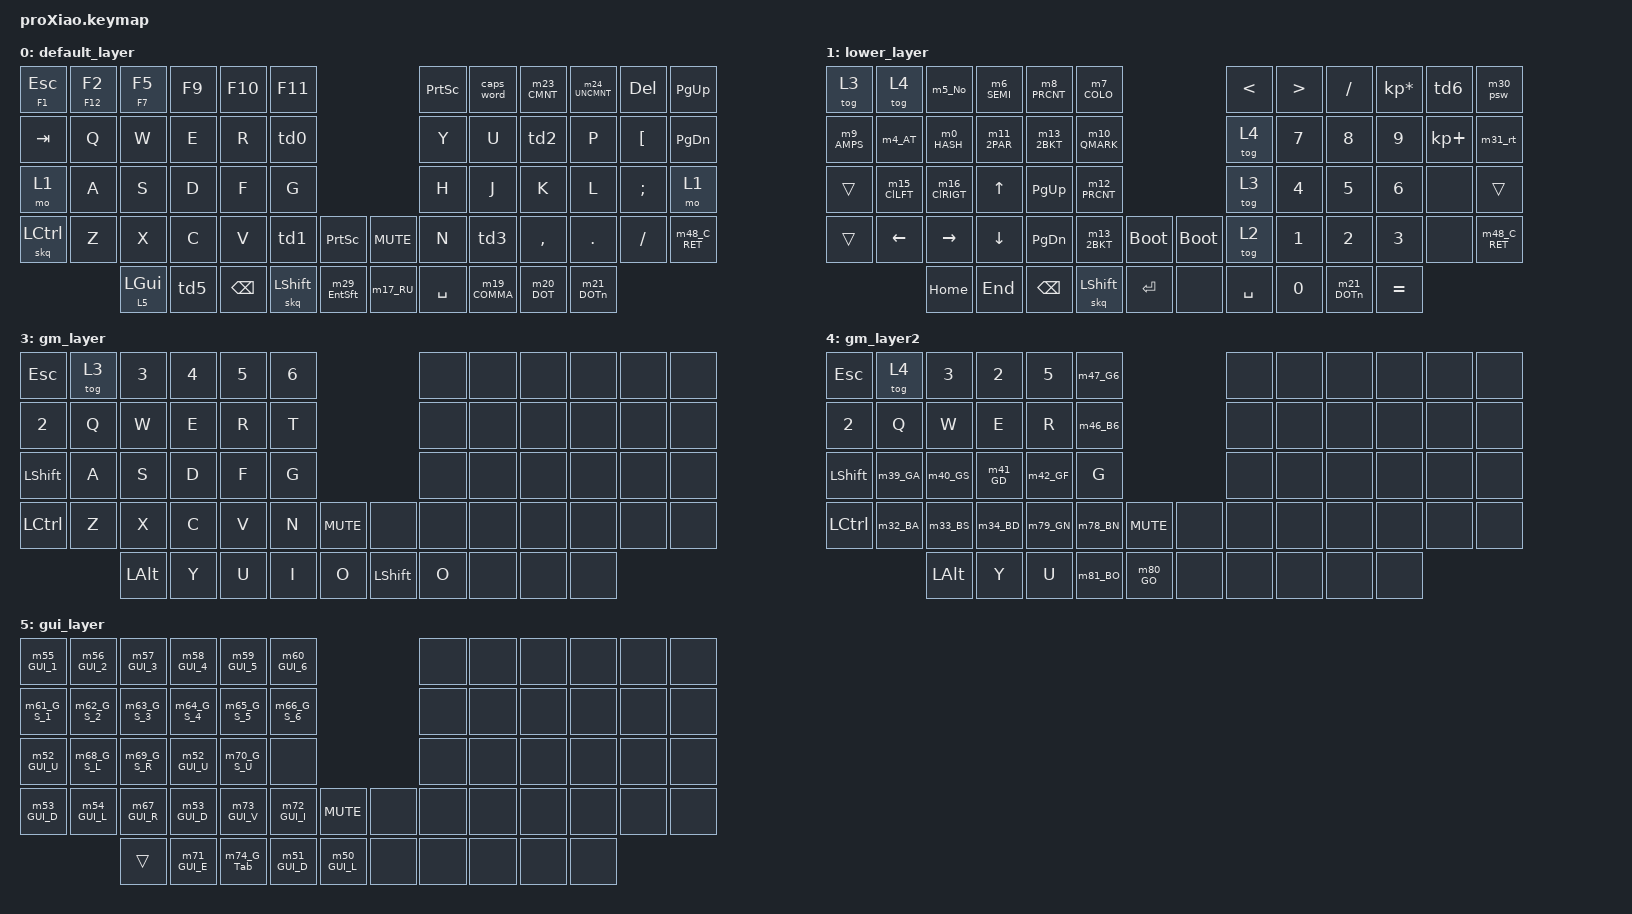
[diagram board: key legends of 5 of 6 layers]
/*
 * Copyright (c) 2020 The ZMK Contributors
 *
 * SPDX-License-Identifier: MIT
 */

#include <behaviors.dtsi>
#include <dt-bindings/zmk/keys.h>
#include <dt-bindings/zmk/bt.h>

&caps_word {
    continue-list = <RBKT>, <GRAVE>, <COMMA>, <DOT>, <FSLH>;
};

/ {
    behaviors {

         td0: tap_dance_0 {
            compatible = "zmk,behavior-tap-dance";
            label = "TAP_DANCE_0";
            #binding-cells = <0>;
            tapping-term-ms = <200>;
            bindings = <&kp T>, <&kp GRAVE>, <&none>;
        };
        td1: tap_dance_1 {
            compatible = "zmk,behavior-tap-dance";
            label = "TAP_DANCE_1";
            #binding-cells = <0>;
            tapping-term-ms = <200>;
            bindings = <&kp B>, <&kp Q>, <&none>;
        };
        td2: tap_dance_2 {
            compatible = "zmk,behavior-tap-dance";
            label = "TAP_DANCE_2";
            #binding-cells = <0>;
            tapping-term-ms = <200>;
            bindings = <&kp I>, <&kp O>, <&none>;
        };
        td3: tap_dance_3 {
            compatible = "zmk,behavior-tap-dance";
            label = "TAP_DANCE_3";
            #binding-cells = <0>;
            tapping-term-ms = <200>;
            bindings = <&kp M>, <&kp RBKT>, <&none>;
        };
        td4: tap_dance_4 {
            compatible = "zmk,behavior-tap-dance";
            label = "TAP_DANCE_4";
            #binding-cells = <0>;
            tapping-term-ms = <200>;
            bindings = <&sk LSHIFT>, <&kp RBKT>, <&none>;
        };
        td5: tap_dance_5 {
            compatible = "zmk,behavior-tap-dance";
            label = "TAP_DANCE_4";
            #binding-cells = <0>;
            tapping-term-ms = <200>;
            bindings = <&kp LALT>, <&m22_AltF4>, <&none>;
        };
        td6: tap_dance_6 {
            compatible = "zmk,behavior-tap-dance";
            label = "TAP_DANCE_6";
            #binding-cells = <0>;
            tapping-term-ms = <200>;
            bindings = <&kp KP_MINUS>, <&kp UNDER>, <&none>;
        };
    };
    macros {
        m0_HASH: m0_HASH {
            label = "m0_HASH";
            compatible = "zmk,behavior-macro";
            #binding-cells = <0>;
            bindings
                = <&macro_press &kp LEFT_ALT>
                , <&macro_tap &kp KP_N3 &kp KP_N5>
                , <&macro_release &kp LEFT_ALT>
                ;
        };
        m1_DQT: m1_DQT {
            label = "m1_DQT";
            compatible = "zmk,behavior-macro";
            #binding-cells = <0>;
            bindings
                = <&macro_press &kp LEFT_ALT>
                , <&macro_tap &kp KP_N3 &kp KP_N4>
                , <&macro_release &kp LEFT_ALT>
                ;
        };
        m2_2DQT: m2_2DQT {
            label = "m2_2DQT";
            compatible = "zmk,behavior-macro";
            #binding-cells = <0>;
            bindings
                = <&macro_press &kp LEFT_ALT>
                , <&macro_tap &kp KP_N3 &kp KP_N4>
                , <&macro_release &kp LEFT_ALT>
                , <&macro_tap &kp LEFT>
                , <&macro_press &kp LEFT_ALT>
                , <&macro_tap &kp KP_N3 &kp KP_N4>
                , <&macro_release &kp LEFT_ALT>
                ;
        };
        m3_EXCL: m3_EXCL {
            label = "m3_EXCL";
            compatible = "zmk,behavior-macro";
            #binding-cells = <0>;
            bindings
                = <&macro_press &kp LEFT_ALT>
                , <&macro_tap &kp KP_N3 &kp KP_N3>
                , <&macro_release &kp LEFT_ALT>
                ;
        };
        m4_AT: m4_AT {
            label = "m4_AT";
            compatible = "zmk,behavior-macro";
            #binding-cells = <0>;
            bindings
                = <&macro_press &kp LEFT_ALT>
                , <&macro_tap &kp KP_N6 &kp KP_N4>
                , <&macro_release &kp LEFT_ALT>
                ;
        };
        m5_No: m5_No {
            label = "m5_No";
            compatible = "zmk,behavior-macro";
            #binding-cells = <0>;
            bindings
                = <&macro_press &kp LEFT_ALT>
                , <&macro_tap &kp KP_N2 &kp KP_N5 &kp KP_N2>
                , <&macro_release &kp LEFT_ALT>
                ;
        };
        m6_SEMI: m6_SEMI {
            label = "m6_SEMI";
            compatible = "zmk,behavior-macro";
            #binding-cells = <0>;
            bindings
                = <&macro_press &kp LEFT_ALT>
                , <&macro_tap &kp KP_N5 &kp KP_N9>
                , <&macro_release &kp LEFT_ALT>
                ;
        };
        m7_COLO: m7_COLO {
            label = "m7_COLO";
            compatible = "zmk,behavior-macro";
            #binding-cells = <0>;
            bindings
                = <&macro_press &kp LEFT_ALT>
                , <&macro_tap &kp KP_N5 &kp KP_N8>
                , <&macro_release &kp LEFT_ALT>
                ;
        };
        m8_PRCNT: m8_PRCNT {
            label = "m8_PRCNT";
            compatible = "zmk,behavior-macro";
            #binding-cells = <0>;
            bindings
                = <&macro_press &kp LEFT_ALT>
                , <&macro_tap &kp KP_N3 &kp KP_N7>
                , <&macro_release &kp LEFT_ALT>
                ;
        };
        m9_AMPS: m9_AMPS {
            label = "m9_AMPS";
            compatible = "zmk,behavior-macro";
            #binding-cells = <0>;
            bindings
                = <&macro_press &kp LEFT_ALT>
                , <&macro_tap &kp KP_N3 &kp KP_N8>
                , <&macro_release &kp LEFT_ALT>
                ;
        };
        m10_QMARK: m10_QMARK {
            label = "m10_QMARK";
            compatible = "zmk,behavior-macro";
            #binding-cells = <0>;
            bindings
                = <&macro_press &kp LEFT_ALT>
                , <&macro_tap &kp KP_N6 &kp KP_N3>
                , <&macro_release &kp LEFT_ALT>
                ;
        };
        m11_2PAR: m11_2PAR {
            label = "m11_2PAR";
            compatible = "zmk,behavior-macro";
            #binding-cells = <0>;
            bindings
                = <&macro_press &kp LEFT_ALT>
                , <&macro_tap &kp KP_N4 &kp KP_N1>
                , <&macro_release &kp LEFT_ALT>
                , <&macro_tap &kp LEFT>
                , <&macro_press &kp LEFT_ALT>
                , <&macro_tap &kp KP_N4 &kp KP_N0>
                , <&macro_release &kp LEFT_ALT>
                ;
        };
        m12_PRCNT: m12_PRCNT {
            label = "m12_PRCNT";
            compatible = "zmk,behavior-macro";
            #binding-cells = <0>;
            bindings
                = <&macro_press &kp LEFT_ALT>
                , <&macro_tap &kp KP_N3 &kp KP_N7>
                , <&macro_release &kp LEFT_ALT>
                ;
        };
        m13_2BKT: m13_2BKT {
            label = "m13_2BKT";
            compatible = "zmk,behavior-macro";
            #binding-cells = <0>;
            bindings
                = <&macro_press &kp LEFT_ALT>
                , <&macro_tap &kp KP_N9 &kp KP_N1>
                , <&macro_release &kp LEFT_ALT>
                , <&macro_tap &kp LEFT>
                , <&macro_press &kp LEFT_ALT>
                , <&macro_tap &kp KP_N9 &kp KP_N3>
                , <&macro_release &kp LEFT_ALT>
                ;
        };
        m14_2BRC: m14_2BRC {
            label = "m14_2BRC";
            compatible = "zmk,behavior-macro";
            #binding-cells = <0>;
            bindings
                = <&macro_press &kp LEFT_ALT>
                , <&macro_tap &kp KP_N1 &kp KP_N2 &kp KP_N3>
                , <&macro_release &kp LEFT_ALT>
                , <&macro_tap &kp LEFT>
                , <&macro_press &kp LEFT_ALT>
                , <&macro_tap &kp KP_N4 &kp KP_N1 &kp KP_N5>
                , <&macro_release &kp LEFT_ALT>
                ;
        };
         m15_ClLFT: m15_ClLFT {
            label = "m15_ClLFT";
            compatible = "zmk,behavior-macro";
            #binding-cells = <0>;
            bindings
                = <&macro_press &kp LCTRL>
                , <&macro_tap &kp LEFT>
                , <&macro_release &kp LCTRL>
                ;
        };
         m16_ClRIGT: m16_ClRIGT {
            label = "m16_ClRIGT";
            compatible = "zmk,behavior-macro";
            #binding-cells = <0>;
            bindings
                = <&macro_press &kp LCTRL>
                , <&macro_tap &kp RIGHT>
                , <&macro_release &kp LCTRL>
                ;
        };
         m17_RU: m17_RU {
            label = "m17_RU";
            compatible = "zmk,behavior-macro";
            #binding-cells = <0>;
            bindings
                = <&macro_press &kp LCTRL>
                , <&macro_press &kp LSHFT>
                , <&macro_tap &kp N8>
                , <&macro_release &kp LSHFT>
                , <&macro_release &kp LCTRL>
                ;
        };
         m18_EN: m18_EN {
            label = "m18_EN";
            compatible = "zmk,behavior-macro";
            #binding-cells = <0>;
            bindings
                = <&macro_press &kp LCTRL>
                , <&macro_press &kp LSHFT>
                , <&macro_tap &kp N9>
                , <&macro_release &kp LSHFT>
                , <&macro_release &kp LCTRL>
                ;
        };
         m19_COMMA: m19_COMMA {
            label = "m19_COMMA";
            compatible = "zmk,behavior-macro";
            #binding-cells = <0>;
            bindings
                = <&macro_press &kp LEFT_ALT>
                , <&macro_tap &kp KP_N4 &kp KP_N4>
                , <&macro_release &kp LEFT_ALT>
                , <&macro_tap &kp SPACE>
                ;
        };
         m20_DOT: m20_DOT {
            label = "m20_DOT";
            compatible = "zmk,behavior-macro";
            #binding-cells = <0>;
            bindings
                = <&macro_press &kp LEFT_ALT>
                , <&macro_tap &kp KP_N4 &kp KP_N6>
                , <&macro_release &kp LEFT_ALT>
                , <&macro_tap &kp SPACE>
                , <&macro_tap &sl LSHFT>
//                , <&macro_tap &skq LSHFT>
                ;
        };
         m21_DOTn: m21_DOTn {
            label = "m21_DOTn";
            compatible = "zmk,behavior-macro";
            #binding-cells = <0>;
            bindings
                = <&macro_press &kp LEFT_ALT>
                , <&macro_tap &kp KP_N4 &kp KP_N6>
                , <&macro_release &kp LEFT_ALT>
                ;
        };
         m22_AltF4: m22_AltF4 {
            label = "m22_AltF4";
            compatible = "zmk,behavior-macro";
            #binding-cells = <0>;
            bindings
                = <&macro_press &kp LEFT_ALT>
                , <&macro_tap &kp F4>
                , <&macro_release &kp LEFT_ALT>
                ;
        };
         m23_CMNT: m23_CMNT {
            label = "m23_CMNT";
            compatible = "zmk,behavior-macro";
            #binding-cells = <0>;
            bindings
                = <&macro_press &kp LCTRL>
                , <&macro_tap &kp BSLH>
                , <&macro_release &kp LCTRL>
                ;
        };
         m24_UNCMNT: m24_UNCMNT {
            label = "m24_UNCMNT";
            compatible = "zmk,behavior-macro";
            #binding-cells = <0>;
            bindings
                = <&macro_press &kp LCTRL>
                , <&macro_press &kp LSHFT>
                , <&macro_tap &kp BSLH>
                , <&macro_release &kp LSHFT>
                , <&macro_release &kp LCTRL>
                ;
        };
         m25_OBND: m25_OBND {
            label = "m25_OBND";
            compatible = "zmk,behavior-macro";
            #binding-cells = <0>;
            bindings
                = <&macro_press &kp LEFT_ALT>
                , <&macro_press &kp LSHFT>
                , <&macro_tap &kp N>
                , <&macro_release &kp LSHFT>
                , <&macro_release &kp LEFT_ALT>
                ;
        };
         m26_OBNU: m26_OBNU {
            label = "m26_OBNU";
            compatible = "zmk,behavior-macro";
            #binding-cells = <0>;
            bindings
                = <&macro_press &kp LEFT_ALT>
                , <&macro_press &kp LSHFT>
                , <&macro_tap &kp P>
                , <&macro_release &kp LSHFT>
                , <&macro_release &kp LEFT_ALT>
                ;
        };
//         m27_OSM: m27_OSM {
//           label = "m27_OSM";
//            compatible = "zmk,behavior-macro";
//            #binding-cells = <0>;
//            bindings
//                = <&macro_tap &sl LSHFT>
//                ;
//        };
         m28_AltDel: m28_AltDel {
           label = "m28_AltDel";
            compatible = "zmk,behavior-macro";
            #binding-cells = <0>;
            bindings
                = <&macro_press &kp LSHFT>
                , <&macro_tap &kp DEL>
                , <&macro_release &kp LSHFT>
                ;
        };
         m29_EntSft: m29_EntSft {
           label = "m29_EntSft";
            compatible = "zmk,behavior-macro";
            #binding-cells = <0>;
            bindings
                = <&macro_tap &kp RET>
                , <&macro_tap &skq LSHFT>
                ;
        };
         m30_psw: m30_psw {
           label = "m30_psw";
            compatible = "zmk,behavior-macro";
            #binding-cells = <0>;
            bindings
                = <&macro_tap &kp N1>
                , <&macro_tap &kp N5>
                , <&macro_tap &kp N7>
                , <&macro_press &kp LCTRL>
                , <&macro_press &kp LSHFT>
                , <&macro_tap &kp N9>
                , <&macro_release &kp LSHFT>
                , <&macro_release &kp LCTRL>
                , <&macro_tap &kp V>
                , <&macro_press &kp LSHFT>
                , <&macro_tap &kp F>
                , <&macro_tap &kp H>
                , <&macro_release &kp LSHFT>
                , <&macro_tap &kp S>
                , <&macro_tap &kp N8>
                , <&macro_tap &kp N5>
                , <&macro_tap &kp N4>
                , <&macro_tap &kp RET>
                ;
        };
         m31_rt: m31_rt {
           label = "m31_rt";
            compatible = "zmk,behavior-macro";
            #binding-cells = <0>;
            bindings
                = <&macro_tap &kp R>
                , <&macro_tap &kp O>
                , <&macro_tap &kp O>
                , <&macro_tap &kp T>
                , <&macro_tap &kp TAB>        
                , <&macro_press &kp LSHFT>
                , <&macro_tap &kp R>
                , <&macro_release &kp LSHFT>
                , <&macro_tap &kp O>
                , <&macro_tap &kp O>
                , <&macro_tap &kp T>
                , <&macro_tap &kp N1>
                , <&macro_tap &kp N4>
                , <&macro_tap &kp N1>
                , <&macro_tap &kp N4>
                , <&macro_tap &kp RET>
                ;
        };
         m32_BA: m32_BA {
           label = "m32_BA";
            compatible = "zmk,behavior-macro";
            #binding-cells = <0>;
            bindings
                = <&macro_tap &kp B>
                , <&macro_tap &kp A>
                , <&macro_tap &kp O>
                ;
        };
         m33_BS: m33_BS {
           label = "m33_BS";
            compatible = "zmk,behavior-macro";
            #binding-cells = <0>;
            bindings
                = <&macro_tap &kp B>
                , <&macro_tap &kp S>
                ;
        };
         m34_BD: m34_BD {
           label = "m34_BD";
            compatible = "zmk,behavior-macro";
            #binding-cells = <0>;
            bindings
                = <&macro_tap &kp B>
                , <&macro_tap &kp D>
                ;
        };
         m35_B1: m35_B1 {
           label = "m35_B2";
            compatible = "zmk,behavior-macro";
            #binding-cells = <0>;
            bindings
                = <&macro_tap &kp B>
                , <&macro_tap &kp N1>
                ;
        };
         m36_BE: m36_BE {
           label = "m36_BE";
            compatible = "zmk,behavior-macro";
            #binding-cells = <0>;
            bindings
                = <&macro_tap &kp B>
                , <&macro_tap &kp E>
                ;
        };
         m37_BR: m37_BR {
           label = "m37_BR";
            compatible = "zmk,behavior-macro";
            #binding-cells = <0>;
            bindings
                = <&macro_tap &kp B>
                , <&macro_tap &kp R>
                ;
        };
         m38_BT: m38_BT {
           label = "m38_BT";
            compatible = "zmk,behavior-macro";
            #binding-cells = <0>;
            bindings
                = <&macro_tap &kp B>
                , <&macro_tap &kp T>
                ;
        };
         m39_GA: m39_GA {
           label = "m39_GA";
            compatible = "zmk,behavior-macro";
            #binding-cells = <0>;
            bindings
                = <&macro_tap &kp G>
                , <&macro_tap &kp A>
                , <&macro_tap &kp O>
                ;
        };
         m40_GS: m40_GS {
           label = "m40_GS";
            compatible = "zmk,behavior-macro";
            #binding-cells = <0>;
            bindings
                = <&macro_tap &kp G>
                , <&macro_tap &kp S>
                ;
        };
         m41_GD: m41_GD {
           label = "m41_GD";
            compatible = "zmk,behavior-macro";
            #binding-cells = <0>;
            bindings
                = <&macro_tap &kp G>
                , <&macro_tap &kp D>
                ;
        };
         m42_GF: m42_GF {
           label = "m42_GF";
            compatible = "zmk,behavior-macro";
            #binding-cells = <0>;
            bindings
                = <&macro_tap &kp G>
                , <&macro_tap &kp F>
                ;
        };
         m43_G1: m43_G1 {
           label = "m43_G1";
            compatible = "zmk,behavior-macro";
            #binding-cells = <0>;
            bindings
                = <&macro_tap &kp G>
                , <&macro_tap &kp N1>
                ;
        };
         m44_BU: m44_BU {
           label = "m44_BU";
            compatible = "zmk,behavior-macro";
            #binding-cells = <0>;
            bindings
                = <&macro_tap &kp B>
                , <&macro_tap &kp U>
                ;
        };
         m45_GU: m45_GU {
           label = "m45_GU";
            compatible = "zmk,behavior-macro";
            #binding-cells = <0>;
            bindings
                = <&macro_tap &kp G>
                , <&macro_tap &kp U>
                ;
        };
         m46_B6: m46_B6 {
           label = "m46_B6";
            compatible = "zmk,behavior-macro";
            #binding-cells = <0>;
            bindings
                = <&macro_tap &kp B>
                , <&macro_tap &kp N6>
                ;
        };
         m47_G6: m47_G6 {
           label = "m47_G6";
            compatible = "zmk,behavior-macro";
            #binding-cells = <0>;
            bindings
                = <&macro_tap &kp G>
                , <&macro_tap &kp N6>
                ;
        };
         m48_C_RET: m48_C_RET {
           label = "m48_C_RET";
            compatible = "zmk,behavior-macro";
            #binding-cells = <0>;
            bindings
                = <&macro_press &kp LCTRL>
                , <&macro_tap &kp RET>
                , <&macro_release &kp LCTRL>
                ;
        };
         m49_GE: m49_GE {
           label = "m49_GE";
            compatible = "zmk,behavior-macro";
            #binding-cells = <0>;
            bindings
                = <&macro_tap &kp G>
                , <&macro_tap &kp E>
                ;
        };
         m50_GUI_L: m50_GUI_L {
           label = "m50_GUI_L";
            compatible = "zmk,behavior-macro";
            #binding-cells = <0>;
            bindings
                = <&macro_press &kp LGUI>
                , <&macro_tap &kp L>
                , <&macro_release &kp LGUI>
                ;
        };
         m51_GUI_D: m51_GUI_D {
           label = "m51_GUI_D";
            compatible = "zmk,behavior-macro";
            #binding-cells = <0>;
            bindings
                = <&macro_press &kp LGUI>
                , <&macro_tap &kp D>
                , <&macro_release &kp LGUI>
                ;
        };
         m52_GUI_U: m52_GUI_U {
           label = "m52_GUI_U";
            compatible = "zmk,behavior-macro";
            #binding-cells = <0>;
            bindings
                = <&macro_press &kp LGUI>
                , <&macro_tap &kp UP>
                , <&macro_release &kp LGUI>
                ;
        };
         m53_GUI_D: m53_GUI_D {
           label = "m53_GUI_D";
            compatible = "zmk,behavior-macro";
            #binding-cells = <0>;
            bindings
                = <&macro_press &kp LGUI>
                , <&macro_tap &kp DOWN>
                , <&macro_release &kp LGUI>
                ;
        };
         m54_GUI_L: m54_GUI_L {
           label = "m54_GUI_L";
            compatible = "zmk,behavior-macro";
            #binding-cells = <0>;
            bindings
                = <&macro_press &kp LGUI>
                , <&macro_tap &kp LEFT>
                , <&macro_release &kp LGUI>
                ;
        };
         m55_GUI_1: m55_GUI_1 {
           label = "m55_GUI_1";
            compatible = "zmk,behavior-macro";
            #binding-cells = <0>;
            bindings
                = <&macro_press &kp LGUI>
                , <&macro_tap &kp N1>
                , <&macro_release &kp LGUI>
                ;
        };
         m56_GUI_2: m56_GUI_2 {
           label = "m56_GUI_2";
            compatible = "zmk,behavior-macro";
            #binding-cells = <0>;
            bindings
                = <&macro_press &kp LGUI>
                , <&macro_tap &kp N2>
                , <&macro_release &kp LGUI>
                ;
        };
         m57_GUI_3: m57_GUI_3 {
           label = "m57_GUI_3";
            compatible = "zmk,behavior-macro";
            #binding-cells = <0>;
            bindings
                = <&macro_press &kp LGUI>
                , <&macro_tap &kp N3>
                , <&macro_release &kp LGUI>
                ;
        };
         m58_GUI_4: m58_GUI_4 {
           label = "m58_GUI_4";
            compatible = "zmk,behavior-macro";
            #binding-cells = <0>;
            bindings
                = <&macro_press &kp LGUI>
                , <&macro_tap &kp N4>
                , <&macro_release &kp LGUI>
                ;
        };
         m59_GUI_5: m59_GUI_5 {
           label = "m59_GUI_5";
            compatible = "zmk,behavior-macro";
            #binding-cells = <0>;
            bindings
                = <&macro_press &kp LGUI>
                , <&macro_tap &kp N5>
                , <&macro_release &kp LGUI>
                ;
        };
         m60_GUI_6: m60_GUI_6 {
           label = "m60_GUI_6";
            compatible = "zmk,behavior-macro";
            #binding-cells = <0>;
            bindings
                = <&macro_press &kp LGUI>
                , <&macro_tap &kp N6>
                , <&macro_release &kp LGUI>
                ;
        };
         m61_G_S_1: m61_G_S_1 {
           label = "m61_G_S_1";
            compatible = "zmk,behavior-macro";
            #binding-cells = <0>;
            bindings
                = <&macro_press &kp LGUI>
                , <&macro_press &kp LSHFT>
                , <&macro_tap &kp N1>
                , <&macro_release &kp LSHFT>
                , <&macro_release &kp LGUI>
                ;
        };
         m62_G_S_2: m62_G_S_2 {
           label = "m62_G_S_2";
            compatible = "zmk,behavior-macro";
            #binding-cells = <0>;
            bindings
                = <&macro_press &kp LGUI>
                , <&macro_press &kp LSHFT>
                , <&macro_tap &kp N2>
                , <&macro_release &kp LSHFT>
                , <&macro_release &kp LGUI>
                ;
        };
         m63_G_S_3: m63_G_S_3 {
           label = "m63_G_S_3";
            compatible = "zmk,behavior-macro";
            #binding-cells = <0>;
            bindings
                = <&macro_press &kp LGUI>
                , <&macro_press &kp LSHFT>
                , <&macro_tap &kp N3>
                , <&macro_release &kp LSHFT>
                , <&macro_release &kp LGUI>
                ;
        };
         m64_G_S_4: m64_G_S_4 {
           label = "m64_G_S_4";
            compatible = "zmk,behavior-macro";
            #binding-cells = <0>;
            bindings
                = <&macro_press &kp LGUI>
                , <&macro_press &kp LSHFT>
                , <&macro_tap &kp N4>
                , <&macro_release &kp LSHFT>
                , <&macro_release &kp LGUI>
                ;
        };
         m65_G_S_5: m65_G_S_5 {
           label = "m65_G_S_5";
            compatible = "zmk,behavior-macro";
            #binding-cells = <0>;
            bindings
                = <&macro_press &kp LGUI>
                , <&macro_press &kp LSHFT>
                , <&macro_tap &kp N5>
                , <&macro_release &kp LSHFT>
                , <&macro_release &kp LGUI>
                ;
        };
         m66_G_S_6: m66_G_S_6 {
           label = "m66_G_S_6";
            compatible = "zmk,behavior-macro";
            #binding-cells = <0>;
            bindings
                = <&macro_press &kp LGUI>
                , <&macro_press &kp LSHFT>
                , <&macro_tap &kp N6>
                , <&macro_release &kp LSHFT>
                , <&macro_release &kp LGUI>
                ;
        };
          m67_GUI_R: m67_GUI_R {
           label = "m67_GUI_R";
            compatible = "zmk,behavior-macro";
            #binding-cells = <0>;
            bindings
                = <&macro_press &kp LGUI>
                , <&macro_tap &kp RIGHT>
                , <&macro_release &kp LGUI>
                ;
        };
         m68_G_S_L: m68_G_S_L {
           label = "m68_G_S_L";
            compatible = "zmk,behavior-macro";
            #binding-cells = <0>;
            bindings
                = <&macro_press &kp LGUI>
                , <&macro_press &kp LSHFT>
                , <&macro_tap &kp LEFT>
                , <&macro_release &kp LSHFT>
                , <&macro_release &kp LGUI>
                ;
        };
         m69_G_S_R: m69_G_S_R {
           label = "m69_G_S_R";
            compatible = "zmk,behavior-macro";
            #binding-cells = <0>;
            bindings
                = <&macro_press &kp LGUI>
                , <&macro_press &kp LSHFT>
                , <&macro_tap &kp RIGHT>
                , <&macro_release &kp LSHFT>
                , <&macro_release &kp LGUI>
                ;
        };
         m70_G_S_U: m70_G_S_U {
           label = "m70_G_S_U";
            compatible = "zmk,behavior-macro";
            #binding-cells = <0>;
            bindings
                = <&macro_press &kp LGUI>
                , <&macro_press &kp LSHFT>
                , <&macro_tap &kp UP>
                , <&macro_release &kp LSHFT>
                , <&macro_release &kp LGUI>
                ;
        };
         m71_GUI_E: m71_GUI_E {
           label = "m71_GUI_E";
            compatible = "zmk,behavior-macro";
            #binding-cells = <0>;
            bindings
                = <&macro_press &kp LGUI>
                , <&macro_tap &kp E>
                , <&macro_release &kp LGUI>
                ;
        };
         m72_GUI_I: m72_GUI_I {
           label = "m72_GUI_I";
            compatible = "zmk,behavior-macro";
            #binding-cells = <0>;
            bindings
                = <&macro_press &kp LGUI>
                , <&macro_tap &kp I>
                , <&macro_release &kp LGUI>
                ;
        };
         m73_GUI_V: m73_GUI_V {
           label = "m73_GUI_V";
            compatible = "zmk,behavior-macro";
            #binding-cells = <0>;
            bindings
                = <&macro_press &kp LGUI>
                , <&macro_tap &kp V>
                , <&macro_release &kp LGUI>
                ;
        };
         m74_G_Tab: m74_G_Tab {
           label = "m74_G_Tab";
            compatible = "zmk,behavior-macro";
            #binding-cells = <0>;
            bindings
                = <&macro_press &kp LGUI>
                , <&macro_tap &kp TAB>
                , <&macro_release &kp LGUI>
                ;
        };
         m75_C_S: m75_C_S {
           label = "m75_C_S";
            compatible = "zmk,behavior-macro";
            #binding-cells = <0>;
            bindings
                = <&macro_press &kp LCTRL>
                , <&macro_tap &kp S>
                , <&macro_release &kp LCTRL>
                ;
        };
         m76_C_C: m76_C_C {
           label = "m76_C_C";
            compatible = "zmk,behavior-macro";
            #binding-cells = <0>;
            bindings
                = <&macro_press &kp LCTRL>
                , <&macro_tap &kp C>
                , <&macro_release &kp LCTRL>
                ;
        };
         m77_C_V: m77_C_V {
           label = "m77_C_V";
            compatible = "zmk,behavior-macro";
            #binding-cells = <0>;
            bindings
                = <&macro_press &kp LCTRL>
                , <&macro_tap &kp V>
                , <&macro_release &kp LCTRL>
                ;
        };
         m78_BN: m78_BN {
           label = "m78_BN";
            compatible = "zmk,behavior-macro";
            #binding-cells = <0>;
            bindings
                = <&macro_tap &kp B>
                , <&macro_tap &kp N>
                ;
        };
         m79_GN: m79_GN {
           label = "m79_GN";
            compatible = "zmk,behavior-macro";
            #binding-cells = <0>;
            bindings
                = <&macro_tap &kp G>
                , <&macro_tap &kp N>
                ;
        };
         m80_GO: m80_GO {
           label = "m80_GO";
            compatible = "zmk,behavior-macro";
            #binding-cells = <0>;
            bindings
                = <&macro_tap &kp G>
                , <&macro_tap &kp O>
                ;
        };
         m81_BO: m81_BO {
           label = "m81_BO";
            compatible = "zmk,behavior-macro";
            #binding-cells = <0>;
            bindings
                = <&macro_tap &kp B>
                , <&macro_tap &kp O>
                ;
        };
         m82_RO: m82_RO {
           label = "m82_RO";
            compatible = "zmk,behavior-macro";
            #binding-cells = <0>;
            bindings
                = <&macro_tap &kp R>
                , <&macro_tap &kp O>
                ;
        };
  };
    combos {
        compatible = "zmk,combos";
        combo_EN {
            timeout-ms = <50>;
            key-positions = <55 56>;
            bindings = <&m18_EN>;
        };
        combo_AltDel {
            timeout-ms = <50>;
            key-positions = <52 53>;
            bindings = <&m28_AltDel>;
        };
        combo_m82 {
            timeout-ms = <50>;
            key-positions = <53 54>;
            bindings = <&m82_RO>;
        };
//        combo_F12 {
//            timeout-ms = <50>;
//            key-positions = <1 13>;
//            bindings = <&kp F12>;
//        };
    };

    behaviors {
      skq: sticky_key_quick_release {
        compatible = "zmk,behavior-sticky-key";
        label = "STICKY_KEY_QUICK_RELEASE";
        #binding-cells = <1>;
        bindings = <&kp>;
        release-after-ms = <1000>;
        quick-release;
        ignore-modifiers;
      };
    };

    keymap {
        compatible = "zmk,keymap";

        default_layer {
// ----------------------------------------------------------------------------------------------------------------
// | Esc(F1) | F2 | F5_7 |  F9 |  F10 | F11_12 |                  |  PSCR | C_W  | Ctr / |  C_S / | DEL |  PGUP  |
// |   TAB   | Q  |  W   |  E  |  R   |  T(ё)  |                  |   Y   |  U   | I(щ)  |   P    |  [  |  PGDW  |
// |  LOWER  | A  |  S   |  D  |  F   |   G    |                  |   H   |  J   |   K   |   L    |  ;  | LOWER  |
// |   CTRL  | Z  |  X   |  C  |  V   |  B(й)  | PSCR  |  | MUTE  |   N   | M(ъ) |   ,   |   .    |  /  | C_ENTR |
//                | GUI  | ALT | BSPC | ^SHFT  | ENTR ^|  |  RU   | SPACE |  ,_  |   ._^ |   .    |
            bindings = <
&mt F1 ESC &mt F12 F2 &mt F7 F5  &kp F9 &kp F10  &kp F11                           &kp PSCRN &caps_word &m23_CMNT &m24_UNCMNT &kp DEL  &kp PG_UP
&kp TAB    &kp Q      &kp W      &kp E  &kp R    &td0                              &kp Y     &kp U      &td2      &kp P       &kp LBKT &kp PG_DN
&mo 1      &kp A      &kp S      &kp D  &kp F    &kp G                             &kp H     &kp J      &kp K     &kp L       &kp SEMI &mo 1
&skq LCTRL &kp Z      &kp X      &kp C  &kp V    &td1       &kp PSCRN   &kp C_MUTE &kp N     &td3       &kp COMMA &kp DOT     &kp FSLH &m48_C_RET
                      &lt 5 LGUI &td5   &kp BSPC &skq LSHFT &m29_EntSft &m17_RU    &kp SPACE &m19_COMMA &m20_DOT  &m21_DOTn
            >;

            sensor-bindings = <&inc_dec_kp F3 LS(F3) &inc_dec_kp C_VOL_UP C_VOL_DN>;
        };

        lower_layer {
// --------------------------------------------------------------------------------------------------------
// |  !  |  ""   |   №   |   ;   |  %   |  :   |                 |   <   |  >  |  /  |  *  |  -  |        |
// |  &  |   @   |   #   |  ( )  | [ ]  |  ?   |                 | tog4  |  7  |  8  |  9  |  +  |        |
// |     | Ctl<- | Ctl-> |   ^   | PGUP |  %   |                 | tog3  |  4  |  5  |  6  |     |        |
// |     |   <-  |  ->   |   v   | PGDW | { }  | boot  |  | boot | tog2  |  1  |  2  |  3  |     | C_ENTR |
//               | Номе  |  End  | BSPC | SHFT | ENTER |  |      | SPACE |  0  |  .  |  =  |
            bindings = <

&tog 3   &tog 4     &m5_No      &m6_SEMI  &m8_PRCNT  &m7_COLO                           &kp LT    &kp GT  &kp SLASH &kp KP_MULTIPLY &td6        &m30_psw
&m9_AMPS &m4_AT     &m0_HASH    &m11_2PAR &m13_2BKT  &m10_QMARK                         &tog 4    &kp N7  &kp N8    &kp N9          &kp KP_PLUS &m31_rt
&trans   &m15_ClLFT &m16_ClRIGT &kp UP    &kp PG_UP  &m12_PRCNT                         &tog 3    &kp N4  &kp N5    &kp N6          &none       &trans
&trans   &kp LEFT   &kp RIGHT   &kp DOWN  &kp PG_DN  &m13_2BKT  &bootloader &bootloader &tog 2    &kp N1  &kp N2    &kp N3          &none       &m48_C_RET
                    &kp HOME    &kp END   &kp BSPC   &skq LSHFT &kp RET     &none       &kp SPACE &kp N0  &m21_DOTn &kp EQUAL
            >;

            sensor-bindings = <&inc_dec_kp C_VOL_UP C_VOL_DN &inc_dec_kp PG_UP PG_DN>;
        };

        raise_layer {
// -----------------------------------------------------------------------------------------------------------------
// |  ESC  |  off  |       |      |      |        |                   |       |     |     | Ctr / | C_S / |        |
// |       |       |       |      |      |        |                   |       |     |     |       |       |        |
// |       | Ctl<- | Ctl-> |  ^   | PGUP |        |                   |       |     |     |       |       |        |
// | LCTRL |  < -  |  ->   |  v   | PGDW |        |                   |       |     |     |       |       | C_ENTR |
//                 | OBNU  | OBND | BSPC | ^ SHFT | ENTER |  | Ctrl S | SPACE |     |     |       |
            bindings = <
&kp ESC   &tog 2     &none       &none       &none     &none                         &none     &none &none &m23_CMNT &m24_UNCMNT &none
&m77_C_V  &none      &none       &none       &none     &none                         &none     &none &none &none     &none       &none
&m76_C_C  &m15_ClLFT &m16_ClRIGT &kp UP      &kp PG_UP &none                         &none     &none &none &none     &none       &none
&kp LCTRL &kp LEFT   &kp RIGHT   &kp DOWN    &kp PG_DN &none     &none      &none    &none     &none &none &none     &none       &m48_C_RET   
                     &m26_OBNU   &m25_OBND   &kp BSPC  &kp LSHFT &m48_C_RET &m75_C_S &kp SPACE &none &none
            >;

            sensor-bindings = <&inc_dec_kp PG_UP PG_DN &inc_dec_kp C_VOL_UP C_VOL_DN>;
        };
        gm_layer {
// All dt2            
// -------------------------------------------------------------------------------------------
// | ESC  | off |  3  |  4  |  5  |  6  |                |     |     |     |     |     |     |
// |  2   |  Q  |  W  |  E  |  R  |  T  |                |     |     |     |     |     |     |
// | SHFT |  A  |  S  |  D  |  F  |  G  |                |     |     |     |     |     |     |
// | CTRL |  Z  |  X  |  C  |  V  |  B  | MUTE |  |      |     |     |     |     |     |     |
//              | ALT |  Y  |  U  |  I  |  O   |  | SHFT |  O  |     |     |     |     
            bindings = <
&kp ESC   &tog 3 &kp N3   &kp N4 &kp N5 &kp N6                     &none &none &none &none &none &none
&kp N2    &kp Q  &kp W    &kp E  &kp R  &kp T                      &none &none &none &none &none &none
&kp LSHFT &kp A  &kp S    &kp D  &kp F  &kp G                      &none &none &none &none &none &none
&kp LCTRL &kp Z  &kp X    &kp C  &kp V  &kp N &kp C_MUTE &none     &none &none &none &none &none &none
                 &kp LALT &kp Y  &kp U  &kp I &kp O      &kp LSHFT &kp O &none &none &none
            >;

            sensor-bindings = <&inc_dec_kp F9 F9 &inc_dec_kp F9 F9>;
        };       
        gm_layer2 {
// Arc dt2            
// -------------------------------------------------------------------------------------------
// | ESC | off |  3  |  4  |  5  | G_6 |                |     |     |     |     |     |     |
// |  2  |  Q  |  W  | G_E | G_U | B_6 |                |     |     |     |     |     |     |
// | G_1 | G_A | G_S | G_D | G_F |  G  |                |     |     |     |     |     |     |
// | B_1 | B_A | B_S | B_D |  V  |  B  | MUTE |  |      |     |     |     |     |     |     |
//             |  Y  | B_E | B_U |  I  | B_T  |  | LSHFT|  O  |     |     |     |     
            bindings = <
&kp ESC   &tog 4  &kp N3   &kp N2  &kp N5  &m47_G6                   &none &none &none &none &none &none
&kp N2    &kp Q   &kp W    &kp E   &kp R   &m46_B6                   &none &none &none &none &none &none
&kp LSHFT &m39_GA &m40_GS  &m41_GD &m42_GF &kp G                     &none &none &none &none &none &none
&kp LCTRL &m32_BA &m33_BS  &m34_BD &m79_GN &m78_BN  &kp C_MUTE &none &none &none &none &none &none &none
                  &kp LALT &kp Y   &kp U   &m81_BO  &m80_GO    &none &none &none &none &none
            >;            
// GT средняя кнопка, GR + GE колесо 
//            sensor-bindings = <&inc_dec_kp &m36_BE &m44_BU &inc_dec_kp PG_UP PG_DN>;
            sensor-bindings = <&inc_dec_kp F9 F9 &inc_dec_kp F9 F9>;
        };
        gui_layer {
// -------------------------------------------------------------------------------------------------------
// | GUI 1 | GUI 2 | GUI 3 | GUI 4 | GUI 5 | GUI 6 |                 |     |     |     |     |     |     |
// | G_S 1 | G_S 2 | G_S 3 | G_S 4 | G_S 5 | G_S 6 |                 |     |     |     |     |     |     |
// | GUI ^ | G_S < | G_S > | GUI ^ | G_S ^ |       |                 |     |     |     |     |     |     |
// | GUI v | GUI < | GUI > | GUI v | GUI V | GUI I | MUTE  |  |      |     |     |     |     |     |     |
//                 |       | GUI E | G_Tab | GUI D | GUI L |  |      |     |     |     |     |     
            bindings = <
&m55_GUI_1 &m56_GUI_2 &m57_GUI_3 &m58_GUI_4 &m59_GUI_5 &m60_GUI_6                  &none &none &none &none &none &none
&m61_G_S_1 &m62_G_S_2 &m63_G_S_3 &m64_G_S_4 &m65_G_S_5 &m66_G_S_6                  &none &none &none &none &none &none
&m52_GUI_U &m68_G_S_L &m69_G_S_R &m52_GUI_U &m70_G_S_U &none                       &none &none &none &none &none &none
&m53_GUI_D &m54_GUI_L &m67_GUI_R &m53_GUI_D &m73_GUI_V &m72_GUI_I &kp C_MUTE &none &none &none &none &none &none &none
                      &trans     &m71_GUI_E &m74_G_Tab &m51_GUI_D &m50_GUI_L &none &none &none &none &none
            >;
            sensor-bindings = <&inc_dec_kp C_VOL_UP C_VOL_DN &inc_dec_kp PG_UP PG_DN>;
        };
    };
};
   
